# TRNG_1.0 register map
Vendor: Texas Instruments
Peripheral module from a debugger description file (folder mspm0l122x_l222x).
Registers are 32-bit, read-write, no defined reset value unless marked. A register's access mark holds for its fields unless they carry their own. Offsets are as the file gives them; lines under a group give offsets from that group; [hi:lo] are bit positions; {n}, {i} and the like mark numbered series; 'fields as' and 'values as' point back to an identical list; <NAME> marks a mode.

## TRNG
0x800 TRNG_GPRCM group
  0x00 TRNG_PWREN — Power enable
    [0] ENABLE — Enable the power
      0=DISABLE (Disable Power); 1=ENABLE (Enable Power)
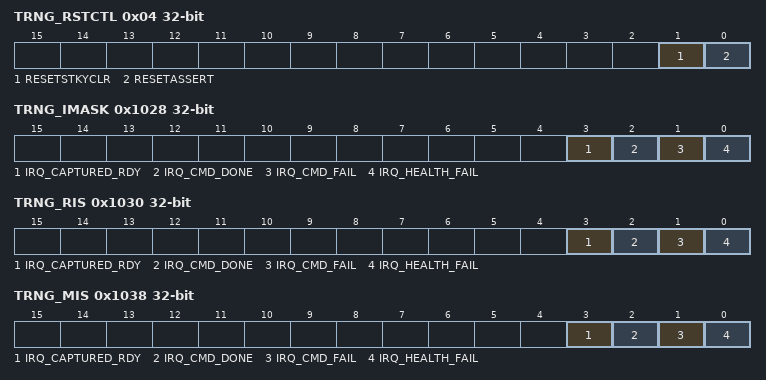
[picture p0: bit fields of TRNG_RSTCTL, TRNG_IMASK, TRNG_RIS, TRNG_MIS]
  0x04 TRNG_RSTCTL — Reset Control
    [1] RESETSTKYCLR — Clear the RESETSTKY bit in the STAT register
      0=NOP (Writing 0 has no effect); 1=CLR (Clear reset sticky bit)
    [0] RESETASSERT — Assert reset to the peripheral
      0=NOP (Writing 0 has no effect); 1=ASSERT (Assert reset)
  0x14 TRNG_GPRCM_STAT ro — Status Register
    [16] RESETSTKY — This bit indicates, if the peripheral was reset, since this bit was cleared by RESETSTKYCLR in the RSTCTL register
      0=NORES (The peripheral has not been reset since this bit was last cleared by RESETSTKYCLR in the RSTCTL register); 1=RESET (The peripheral was reset since the last bit clear)
0x1020 TRNG_IIDX ro — Interrupt index
  [7:0] STAT — Interrupt index status
    0=NO_INTR (No bit is set means there is no pending interrupt request); 1=IRQ_HEALTH_FAIL (Indicates that a health test has failed. The TRNG is in an error state until the interrupt is cleared.); 2=IRQ_CMD_FAIL (Indicates that the just issued command was rejected and is not being performed.); 3=IRQ_CMD_DONE (Indicates that the current command/mode is done. This may have different meanings based on the mode: OFF --> Power has been turned off PWRUP_DIG --> Digital powerup tests are done PWRUP_ANA --> Analog powerup tests are done NORM_FUNC --> No IRQ, since mode runs indefinitely until a new command is issued); 4=IRQ_CAPTURED_RDY (Indicates that the captured word buffer is ready to be copied to memory)
0x1028 TRNG_IMASK — Interrupt mask
  [all] fields
    0=DISABLED (Interrupt is masked out); 1=ENABLED (Interrupt will request an interrupt service routine and corresponding bit in MIS will be set)
  [3] IRQ_CAPTURED_RDY — Mask for IRQ_CAPTURED_RDY. Indicates to the CPU that the Captured Word is ready to be read.
  [2] IRQ_CMD_DONE — Mask for IRQ_CMD_DONE. Indicates that a command has finished
  [1] IRQ_CMD_FAIL — Masked interrupt source for IRQ_CMD_FAIL. Indicates that the just issued command/mode has been rejected.
  [0] IRQ_HEALTH_FAIL — Mask for IRQ_HEALTH_FAIL. Indicates that a health test has failed.
0x1030 TRNG_RIS ro — Raw interrupt status
  [3] IRQ_CAPTURED_RDY — Indicates to the CPU that the Captured Word is ready to be read. Reading the IIDX will clear this interrupt.
    0=CLR (IRQ_CAPTURED_READY did not occur); 1=SET (IRQ_CAPTURED_READY occurred)
  [2] IRQ_CMD_DONE — Raw interrupt source for IRQ_CMD_DONE. Indicates that the issued command/mode has completed.
    0=CLR (IRQ_CMD_DONE did not occur); 1=SET (IRQ_CMD_DONE occurred)
  [1] IRQ_CMD_FAIL — Masked interrupt source for IRQ_CMD_FAIL. Indicates that the just issued command/mode has been rejected.
    0=CLR (IRQ_CMD_FAIL did not occur); 1=SET (IRQ_CMD_FAIL occurred)
  [0] IRQ_HEALTH_FAIL — Indicates to the CPU that any of the health tests have failed. Reading the IIDX will clear this interrupt.
    values as IRQ_CAPTURED_RDY
0x1038 TRNG_MIS ro — Masked interrupt status
  [3] IRQ_CAPTURED_RDY — Masked interrupt result for CAPTURED_READY. Indicates to the CPU that the Captured Word is ready to be read. Reading the IIDX will clear this interrupt.
    0=CLR (IRQ_CAPTURED_READY did not request an interrupt service routine); 1=SET (IRQ_CAPTURED_READY requests an interrupt service routine)
  [2] IRQ_CMD_DONE — Masked interrupt source for IRQ_CMD_DONE. Indicates that the issued command/mode has completed.
    0=CLR (IRQ_CAPTURED_READY did not request an interrupt service routine); 1=SET (IRQ_CMD_DONE requests an interrupt service routine)
  [1] IRQ_CMD_FAIL — Masked interrupt source for IRQ_CMD_FAIL. Indicates that the just issued command/mode has been rejected.
    0=CLR (IRQ_CMD_FAIL did not request an interrupt service routine); 1=SET (IRQ_CMD_FAIL requests an interrupt service routine)
  [0] IRQ_HEALTH_FAIL — Masked interrupt result for HEALTH_FAIL. Indicates to the CPU that any of the health tests have failed for the latest 1024-bit window.
    values as IRQ_CAPTURED_RDY
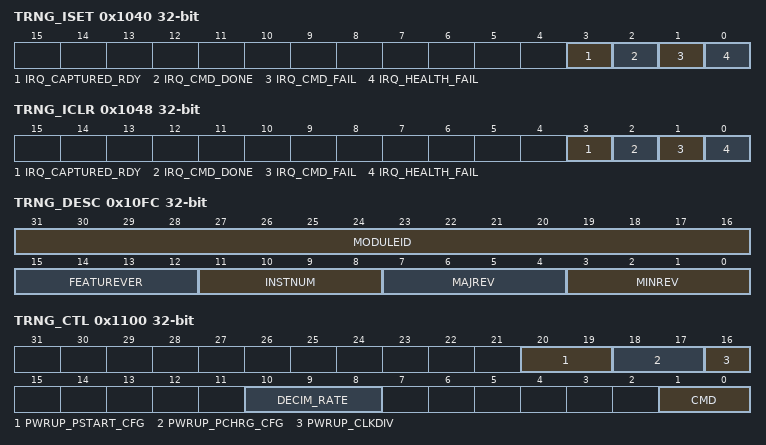
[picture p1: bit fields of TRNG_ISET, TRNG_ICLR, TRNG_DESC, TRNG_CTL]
0x1040 TRNG_ISET — Interrupt set
  [3] IRQ_CAPTURED_RDY — Indicates to the CPU that the Captured Word is ready to be read. Reading the IIDX or DATA_CAPTURE registers will clear this interrupt.
    0=NO_EFFECT (Writing a 0 has no effect); 1=SET (RIS bit corresponding to CAPTURED_READY is set)
  [2] IRQ_CMD_DONE — Write to turn on CMD_DONE IRQ. Indicates that the last issued TRNG command has finished.
    0=NO_EFFECT (Writing a 0 has no effect.); 1=SET (RIS bit corresponding to CMD_DONE is set)
  [1] IRQ_CMD_FAIL — Masked interrupt source for IRQ_CMD_FAIL. Indicates that the just issued command/mode has been rejected.
    0=NO_EFFECT (Writing a 0 has no effect.); 1=SET (RIS bit corresponding to CMD_FAIL is set)
  [0] IRQ_HEALTH_FAIL — Indicates to the CPU that any of the health tests have failed. Reading the IIDX or DATA_CAPTURE registers will clear this interrupt.
    0=NO_EFFECT (Writing a 0 has no effect); 1=SET (RIS bit corresponding to HEALTH_FAIL is set)
0x1048 TRNG_ICLR — Interrupt clear
  [3] IRQ_CAPTURED_RDY — Indicates to the CPU that the Captured Word is ready to be read. Reading the IIDX or DATA_CAPTURE registers will clear this interrupt.
    0=NO_EFFECT (Writing a 0 has no effect); 1=CLR (RIS bit corresponding to CAPTURED_READY is cleared)
  [2] IRQ_CMD_DONE — Write to turn off CMD_DONE IRQ. Indicates that the last issued TRNG command has finished.
    0=NO_EFFECT (Writing a 0 has no effect.); 1=CLR (RIS bit corresponding to CMD_DONE is cleared)
  [1] IRQ_CMD_FAIL — Masked interrupt source for IRQ_CMD_FAIL. Indicates that the just issued command/mode has been rejected.
    0=NO_EFFECT (Writing a 0 has no effect.); 1=CLR (RIS bit corresponding to CMD_FAIL is cleared)
  [0] IRQ_HEALTH_FAIL — Indicates to the CPU that any of the health tests have failed. Reading the IIDX or DATA_CAPTURE registers will clear this interrupt.
    values as IRQ_CAPTURED_RDY
0x10FC TRNG_DESC — Module descriptions
  [31:16] MODULEID — Module Identifier - An internal TI page has been created to request unique module IDs
  [15:12] FEATUREVER — Feature Set for the module *instance*
  [11:8] INSTNUM — Instance Number within the device. This will be a parameter to the RTL for modules that can have multiple instances
  [7:4] MAJREV — Major rev of the IP
  [3:0] MINREV — Minor rev of the IP
0x1100 TRNG_CTL — Controls the command and decimation rate
  [20:19] PWRUP_PSTART_CFG — Configure pusle startup sequence length b00 = Disabled b01 = rise at 10us, fall at 50us b10 = rise at 10us, fall at 70us (default) b11 = rise at 10us, fall at 90us
  [18:17] PWRUP_PCHRG_CFG — Configure PCHARGE sequence length b00 = Disabled b01 = 20 us PCHARGE b10 = 30 us PCHARGE (default) b11 = 40 us PCHARGE
  [16] PWRUP_CLKDIV — When '1', the powerup sequence will take twice as long (i.e., clock frequency halved)
  [10:8] DECIM_RATE — Set decimation rate. Decimate by n 0x0 = Decimation by 1 (no decimation) 0x1 = Decimation by 2 (Skip every other sample) 0x7 = Decimation by 8 (Take every 8th sample)
  [1:0] CMD — Sets the TRNG mode through a command. The mode will not be updated until the previous command is done, as indicated by IRQ_CMD_DONE. 00 --> OFF 01 --> PWRUP_DIG 10 --> PWRUP_ANA 11 --> NORM_FUNC
    0=PWR_OFF (Turns the power off of the analog source and clocks the digital interface); 1=PWRUP_DIG (Initiates the powerup test sequence for the digital components. This verifies that the digital components are properly working. IRQ_CMD_DONE indicates that the test is done. The results of this test are in bits 0:6 in TEST_RESULTS register); 2=PWRUP_ANA (Initiates the powerup test sequence for the analog TRNG. This verifies that the analog component is generating sequences with enough entropy. IRQ_CMD_DONE indicates that the test is done. The results of this test are in bit 7 in TEST_RESULTS register); 3=NORM_FUNC (Normal operating mode for TRNG. All components are turned on.)
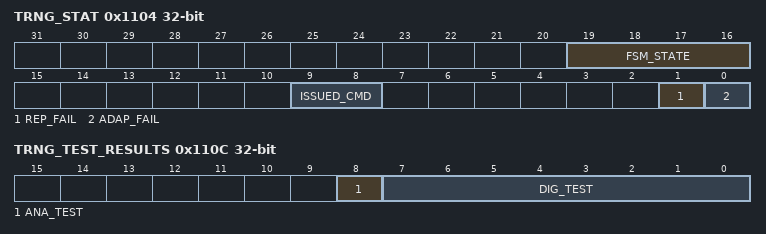
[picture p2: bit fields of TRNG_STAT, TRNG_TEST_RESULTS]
0x1104 TRNG_STAT access per field — Status register that informs health test results and last issued command
  [19:16] FSM_STATE ro — Current state of the front end FSM (behind a clock domain crossing). 2 reads are REQUIRED as there is a chance of metastability when reading this States: 0000: OFF 0001: PWRUP_ES 0011: NORM_FUNC 0111: TEST_DIG 1011: TEST_ANA 1010: ERROR 0010: PWRDOWN_ES
  [9:8] ISSUED_CMD ro — Indicates the last accepted command that is issued to the TRNG interface. Upon writing a valid command, this register will update and the command will be in progress until CMD_DONE_IRQ is set. CMD_DONE_IRQ indicates that the state is in PWROFF, NORM_FUNC, or ERROR. These states will accept new commands. 00 --> OFF 01 --> PWRUP_DIG 10 --> PWRUP_ANA 11 --> NORM_FUNC
  [1] REP_FAIL ro — Indicates that the repetition counter test caused the most recent failure. Thus, the health count numbers are most likely not for a complete 1024-bit window.
  [0] ADAP_FAIL rw — Indicates that the Adaptive Proportion Test (1,2,3, or 4-bit counters) failed by having too many or too few counted samples in the last 1024 bit window.
0x1108 TRNG_DATA_CAPTURE access not given — Captured word buffer of RNG data
0x110C TRNG_TEST_RESULTS — Test results from TEST_ANA and TEST_DIG
  [8] ANA_TEST — Runs through 4096 samples from an enabled entropy source and verifies that none of the health tests failed, indicating sufficient entropy was produced by the analog components
  [7:0] DIG_TEST — Bit 0 indicates if the first decimation rate test and health test(verifies conditioning, decimation, and captured buffer) fails and Bit 1 indicates if the second decimation test and health test fails Bit 0 - decim_test0 (decim = 0x0) Bit 1 - decim_test1 (decim = 0x1) ...
0x1110 TRNG_CLKDIVIDE — Clock Divider
  [2:0] RATIO — Selects divide ratio of module clock
    0=DIV_BY_1 (Do not divide clock source); 1=DIV_BY_2 (Divide clock source by 2); 3=DIV_BY_4 (Divide clock source by 4); 5=DIV_BY_6 (Divide clock source by 6); 7=DIV_BY_8 (Divide clock source by 8)
